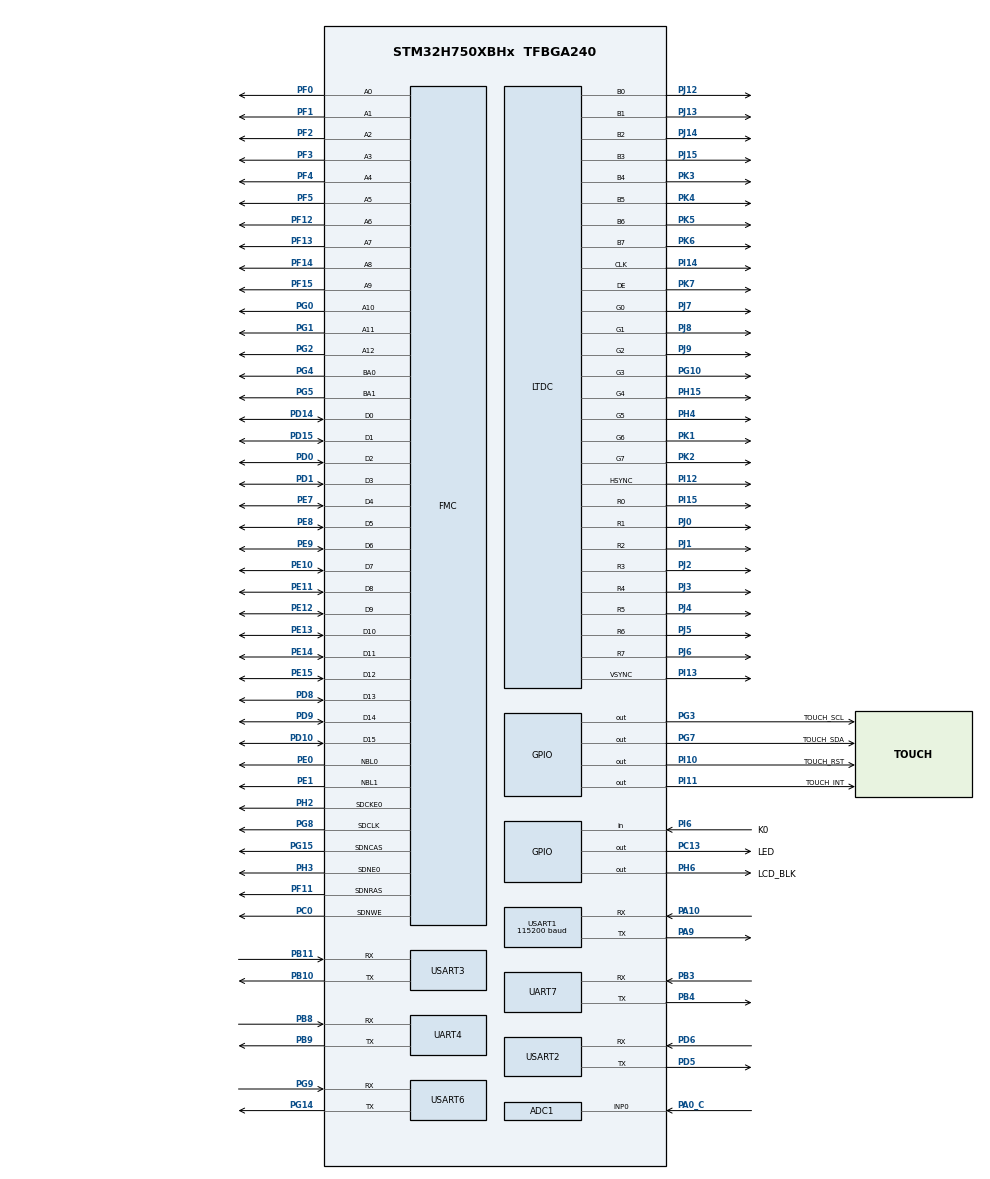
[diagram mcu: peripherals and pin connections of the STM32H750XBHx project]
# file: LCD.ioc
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ADC1.Channel-0\#ChannelRegularConversion=ADC_CHANNEL_0
ADC1.ClockPrescaler=ADC_CLOCK_ASYNC_DIV4
ADC1.ExternalTrigConv=ADC_EXTERNALTRIG_T8_TRGO
ADC1.NbrOfConversionFlag=1
ADC1.OffsetNumber-0\#ChannelRegularConversion=ADC_OFFSET_NONE
ADC1.OffsetSignedSaturation-0\#ChannelRegularConversion=DISABLE
ADC1.Rank-0\#ChannelRegularConversion=1
ADC1.Resolution=ADC_RESOLUTION_12B
ADC1.SamplingTime-0\#ChannelRegularConversion=ADC_SAMPLETIME_2CYCLES_5
ADC1.master=1
CORTEX_M7.AccessPermission-Cortex_Memory_Protection_Unit_Region0_Settings=MPU_REGION_FULL_ACCESS
CORTEX_M7.BaseAddress-Cortex_Memory_Protection_Unit_Region0_Settings=0xC0000000
CORTEX_M7.CPU_DCache=Enabled
CORTEX_M7.CPU_ICache=Enabled
CORTEX_M7.DisableExec-Cortex_Memory_Protection_Unit_Region0_Settings=MPU_INSTRUCTION_ACCESS_ENABLE
CORTEX_M7.Enable-Cortex_Memory_Protection_Unit_Region0_Settings=MPU_REGION_ENABLE
CORTEX_M7.Enable-Cortex_Memory_Protection_Unit_Region10_Settings=__NULL
CORTEX_M7.Enable-Cortex_Memory_Protection_Unit_Region11_Settings=__NULL
CORTEX_M7.Enable-Cortex_Memory_Protection_Unit_Region12_Settings=__NULL
CORTEX_M7.Enable-Cortex_Memory_Protection_Unit_Region13_Settings=__NULL
CORTEX_M7.Enable-Cortex_Memory_Protection_Unit_Region14_Settings=__NULL
CORTEX_M7.Enable-Cortex_Memory_Protection_Unit_Region15_Settings=__NULL
CORTEX_M7.Enable-Cortex_Memory_Protection_Unit_Region1_Settings=__NULL
CORTEX_M7.Enable-Cortex_Memory_Protection_Unit_Region2_Settings=__NULL
CORTEX_M7.Enable-Cortex_Memory_Protection_Unit_Region3_Settings=__NULL
CORTEX_M7.Enable-Cortex_Memory_Protection_Unit_Region4_Settings=__NULL
CORTEX_M7.Enable-Cortex_Memory_Protection_Unit_Region5_Settings=__NULL
CORTEX_M7.Enable-Cortex_Memory_Protection_Unit_Region6_Settings=__NULL
CORTEX_M7.Enable-Cortex_Memory_Protection_Unit_Region7_Settings=__NULL
CORTEX_M7.Enable-Cortex_Memory_Protection_Unit_Region8_Settings=__NULL
CORTEX_M7.Enable-Cortex_Memory_Protection_Unit_Region9_Settings=__NULL
CORTEX_M7.IsBufferable-Cortex_Memory_Protection_Unit_Region0_Settings=MPU_ACCESS_NOT_BUFFERABLE
CORTEX_M7.IsCacheable-Cortex_Memory_Protection_Unit_Region0_Settings=MPU_ACCESS_CACHEABLE
CORTEX_M7.IsShareable-Cortex_Memory_Protection_Unit_Region0_Settings=MPU_ACCESS_NOT_SHAREABLE
CORTEX_M7.MPU_Control=MPU_PRIVILEGED_DEFAULT
CORTEX_M7.Size-Cortex_Memory_Protection_Unit_Region0_Settings=MPU_REGION_SIZE_32MB
CORTEX_M7.TypeExtField-Cortex_Memory_Protection_Unit_Region0_Settings=MPU_TEX_LEVEL0
CORTEX_M7.default_mode_Activation=0
DMA2D.ColorMode=DMA2D_OUTPUT_RGB565
FMC.BankMapConfig=FMC_SWAPBMAP_DISABLE
FMC.CASLatency1=FMC_SDRAM_CAS_LATENCY_3
FMC.ColumnBitsNumber1=FMC_SDRAM_COLUMN_BITS_NUM_9
FMC.ExitSelfRefreshDelay1=7
FMC.LoadToActiveDelay1=2
FMC.RCDDelay1=2
FMC.RPDelay1=2
FMC.ReadBurst1=FMC_SDRAM_RBURST_ENABLE
FMC.ReadPipeDelay1=FMC_SDRAM_RPIPE_DELAY_1
FMC.RowBitsNumber1=FMC_SDRAM_ROW_BITS_NUM_13
FMC.RowCycleDelay1=7
FMC.SDBank1=FMC_SDRAM_BANK1
FMC.SDClockPeriod1=FMC_SDRAM_CLOCK_PERIOD_2
FMC.SelfRefreshTime1=4
FMC.WriteProtection1=FMC_SDRAM_WRITE_PROTECTION_DISABLE
FMC.WriteRecoveryTime1=3
FREERTOS.BinarySemaphores01=ADCValue,Dynamic,NULL,Available
FREERTOS.Tasks01=TouchgfxTask,24,4096,vTouchgfxTask,Default,NULL,Static,TouchgfxTaskBuffer,TouchgfxTaskControlBlock
FREERTOS.configTIMER_TASK_STACK_DEPTH=4096
LTDC.ActiveH=480
LTDC.ActiveW=800
LTDC.Alpha0_L0=0
LTDC.Alpha_L0=255
LTDC.BlendingFactor1_L0=LTDC_BLENDING_FACTOR1_CA
LTDC.BlendingFactor2_L0=LTDC_BLENDING_FACTOR2_CA
LTDC.Blue=0
LTDC.Blue_L0=0
LTDC.DEPolarity=LTDC_DEPOLARITY_AL
LTDC.FBStartAdress_L0=0xC0000000
LTDC.Green=0
LTDC.Green_L0=0
LTDC.HBP=80
LTDC.HFP=200
LTDC.HSPolarity=LTDC_HSPOLARITY_AL
LTDC.HSync=1
LTDC.ImageHeight_L0=480
LTDC.ImageWidth_L0=800
LTDC.Layers=0
LTDC.PCPolarity=LTDC_PCPOLARITY_IPC
LTDC.PixelFormat_L0=LTDC_PIXEL_FORMAT_RGB565
LTDC.Red=0
LTDC.Red_L0=0
LTDC.VBP=40
LTDC.VFP=22
LTDC.VSPolarity=LTDC_VSPOLARITY_AL
LTDC.VSync=1
LTDC.WindowX0_L0=0
LTDC.WindowX1_L0=800
LTDC.WindowY0_L0=0
LTDC.WindowY1_L0=480
Mcu.Family=STM32H7
Mcu.Name=STM32H750XBHx
Mcu.Package=TFBGA240
NVIC.ADC_IRQn=true\:7\:0\:true\:false\:true\:true\:true\:true\:true
NVIC.DMA2D_IRQn=true\:5\:0\:true\:false\:true\:true\:true\:true\:true
NVIC.LTDC_IRQn=true\:5\:0\:true\:false\:true\:true\:true\:true\:true
NVIC.PriorityGroup=NVIC_PRIORITYGROUP_4
NVIC.TIM17_IRQn=true\:5\:0\:false\:false\:true\:true\:true\:true\:true
NVIC.TIM6_DAC_IRQn=true\:15\:0\:false\:false\:true\:false\:false\:true\:true
NVIC.TIM8_UP_TIM13_IRQn=true\:5\:0\:false\:false\:true\:true\:true\:true\:true
NVIC.TimeBase=TIM6_DAC_IRQn
NVIC.TimeBaseIP=TIM6
NVIC.UART4_IRQn=true\:6\:0\:true\:false\:true\:true\:true\:true\:true
NVIC.UART7_IRQn=true\:6\:0\:true\:false\:true\:true\:true\:true\:true
NVIC.USART1_IRQn=true\:5\:0\:false\:false\:true\:true\:true\:true\:true
NVIC.USART2_IRQn=true\:5\:0\:false\:false\:true\:true\:true\:true\:true
NVIC.USART3_IRQn=true\:5\:0\:false\:false\:true\:true\:true\:true\:true
NVIC.USART6_IRQn=true\:5\:0\:false\:false\:true\:true\:true\:true\:true
PA0_C.Signal=ADCx_INP0
PA10.Mode=Asynchronous
PA10.Signal=USART1_RX
PA9.Mode=Asynchronous
PA9.Signal=USART1_TX
PB10.Mode=Asynchronous
PB10.Signal=USART3_TX
PB11.Mode=Asynchronous
PB11.Signal=USART3_RX
PB3\ (JTDO/TRACESWO).Mode=Asynchronous
PB3\ (JTDO/TRACESWO).Signal=UART7_RX
PB4\ (NJTRST).Mode=Asynchronous
PB4\ (NJTRST).Signal=UART7_TX
PB8.Mode=Asynchronous
PB8.Signal=UART4_RX
PB9.Mode=Asynchronous
PB9.Signal=UART4_TX
PC0.Signal=FMC_SDNWE
PC13.GPIO_Label=LED
PC13.PinState=GPIO_PIN_SET
PC13.Signal=GPIO_Output
PD0.Signal=FMC_D2_DA2
PD1.Signal=FMC_D3_DA3
PD10.Signal=FMC_D15_DA15
PD14.Signal=FMC_D0_DA0
PD15.Signal=FMC_D1_DA1
PD5.Mode=Asynchronous
PD5.Signal=USART2_TX
PD6.Mode=Asynchronous
PD6.Signal=USART2_RX
PD8.Signal=FMC_D13_DA13
PD9.Signal=FMC_D14_DA14
PE0.Signal=FMC_NBL0
PE1.Signal=FMC_NBL1
PE10.Signal=FMC_D7_DA7
PE11.Signal=FMC_D8_DA8
PE12.Signal=FMC_D9_DA9
PE13.Signal=FMC_D10_DA10
PE14.Signal=FMC_D11_DA11
PE15.Signal=FMC_D12_DA12
PE7.Signal=FMC_D4_DA4
PE8.Signal=FMC_D5_DA5
PE9.Signal=FMC_D6_DA6
PF0.Signal=FMC_A0
PF1.Signal=FMC_A1
PF11.Signal=FMC_SDNRAS
PF12.Signal=FMC_A6
PF13.Signal=FMC_A7
PF14.Signal=FMC_A8
PF15.Signal=FMC_A9
PF2.Signal=FMC_A2
PF3.Signal=FMC_A3
PF4.Signal=FMC_A4
PF5.Signal=FMC_A5
PF7.GPIO_Speed=GPIO_SPEED_FREQ_VERY_HIGH
PF7.Signal=QUADSPI_BK1_IO2
PF8.GPIO_Speed=GPIO_SPEED_FREQ_VERY_HIGH
PF8.Signal=QUADSPI_BK1_IO0
PF9.GPIO_Speed=GPIO_SPEED_FREQ_VERY_HIGH
PF9.Signal=QUADSPI_BK1_IO1
PG0.Signal=FMC_A10
PG1.Signal=FMC_A11
PG10.GPIO_Speed=GPIO_SPEED_FREQ_VERY_HIGH
PG10.Mode=RGB888
PG10.Signal=LTDC_G3
PG14.Mode=Asynchronous
PG14.Signal=USART6_TX
PG15.Signal=FMC_SDNCAS
PG2.Signal=FMC_A12
PG3.GPIO_Label=TOUCH_SCL
PG3.GPIO_ModeDefaultOutputPP=GPIO_MODE_OUTPUT_OD
PG3.GPIO_PuPd=GPIO_NOPULL
PG3.PinState=GPIO_PIN_SET
PG3.Signal=GPIO_Output
PG4.Signal=FMC_A14_BA0
PG5.Signal=FMC_A15_BA1
PG6.GPIO_Speed=GPIO_SPEED_FREQ_VERY_HIGH
PG6.Signal=QUADSPI_BK1_NCS
PG7.GPIO_Label=TOUCH_SDA
PG7.GPIO_ModeDefaultOutputPP=GPIO_MODE_OUTPUT_OD
PG7.GPIO_PuPd=GPIO_NOPULL
PG7.PinState=GPIO_PIN_SET
PG7.Signal=GPIO_Output
PG8.Signal=FMC_SDCLK
PG9.Mode=Asynchronous
PG9.Signal=USART6_RX
PH0-OSC_IN\ (PH0).Mode=HSE-External-Oscillator
PH0-OSC_IN\ (PH0).Signal=RCC_OSC_IN
PH1-OSC_OUT\ (PH1).Mode=HSE-External-Oscillator
PH1-OSC_OUT\ (PH1).Signal=RCC_OSC_OUT
PH10.GPIO_Speed=GPIO_SPEED_FREQ_VERY_HIGH
PH10.Signal=DCMI_D1
PH12.GPIO_Speed=GPIO_SPEED_FREQ_VERY_HIGH
PH12.Signal=DCMI_D3
PH15.GPIO_Speed=GPIO_SPEED_FREQ_VERY_HIGH
PH15.Mode=RGB888
PH15.Signal=LTDC_G4
PH2.Mode=SdramChipSelect1_1
PH2.Signal=FMC_SDCKE0
PH3.Mode=SdramChipSelect1_1
PH3.Signal=FMC_SDNE0
PH4.GPIO_Speed=GPIO_SPEED_FREQ_VERY_HIGH
PH4.Mode=RGB888
PH4.Signal=LTDC_G5
PH6.GPIO_Label=LCD_BLK
PH6.PinState=GPIO_PIN_SET
PH6.Signal=GPIO_Output
PH9.GPIO_Speed=GPIO_SPEED_FREQ_VERY_HIGH
PH9.Signal=DCMI_D0
PI10.GPIO_Label=TOUCH_RST
PI10.GPIO_PuPd=GPIO_PULLUP
PI10.PinState=GPIO_PIN_SET
PI10.Signal=GPIO_Output
PI11.GPIO_Label=TOUCH_INT
PI11.GPIO_PuPd=GPIO_PULLUP
PI11.Signal=GPIO_Output
PI12.GPIO_Speed=GPIO_SPEED_FREQ_VERY_HIGH
PI12.Mode=RGB888
PI12.Signal=LTDC_HSYNC
PI13.GPIO_Speed=GPIO_SPEED_FREQ_VERY_HIGH
PI13.Mode=RGB888
PI13.Signal=LTDC_VSYNC
PI14.GPIO_Speed=GPIO_SPEED_FREQ_VERY_HIGH
PI14.Mode=RGB888
PI14.Signal=LTDC_CLK
PI15.GPIO_Speed=GPIO_SPEED_FREQ_VERY_HIGH
PI15.Mode=RGB888
PI15.Signal=LTDC_R0
PI6.GPIO_Label=K0
PI6.GPIO_PuPd=GPIO_PULLUP
PI6.Signal=GPIO_Input
PJ0.GPIO_Speed=GPIO_SPEED_FREQ_VERY_HIGH
PJ0.Mode=RGB888
PJ0.Signal=LTDC_R1
PJ1.GPIO_Speed=GPIO_SPEED_FREQ_VERY_HIGH
PJ1.Mode=RGB888
PJ1.Signal=LTDC_R2
PJ12.GPIO_Speed=GPIO_SPEED_FREQ_VERY_HIGH
PJ12.Mode=RGB888
PJ12.Signal=LTDC_B0
PJ13.GPIO_Speed=GPIO_SPEED_FREQ_VERY_HIGH
PJ13.Mode=RGB888
PJ13.Signal=LTDC_B1
PJ14.GPIO_Speed=GPIO_SPEED_FREQ_VERY_HIGH
PJ14.Mode=RGB888
PJ14.Signal=LTDC_B2
PJ15.GPIO_Speed=GPIO_SPEED_FREQ_VERY_HIGH
PJ15.Mode=RGB888
PJ15.Signal=LTDC_B3
PJ2.GPIO_Speed=GPIO_SPEED_FREQ_VERY_HIGH
PJ2.Mode=RGB888
PJ2.Signal=LTDC_R3
PJ3.GPIO_Speed=GPIO_SPEED_FREQ_VERY_HIGH
PJ3.Mode=RGB888
PJ3.Signal=LTDC_R4
PJ4.GPIO_Speed=GPIO_SPEED_FREQ_VERY_HIGH
PJ4.Mode=RGB888
PJ4.Signal=LTDC_R5
PJ5.GPIO_Speed=GPIO_SPEED_FREQ_VERY_HIGH
PJ5.Mode=RGB888
PJ5.Signal=LTDC_R6
PJ6.GPIO_Speed=GPIO_SPEED_FREQ_VERY_HIGH
PJ6.Mode=RGB888
PJ6.Signal=LTDC_R7
PJ7.GPIO_Speed=GPIO_SPEED_FREQ_VERY_HIGH
PJ7.Mode=RGB888
PJ7.Signal=LTDC_G0
PJ8.GPIO_Speed=GPIO_SPEED_FREQ_VERY_HIGH
PJ8.Mode=RGB888
PJ8.Signal=LTDC_G1
PJ9.GPIO_Speed=GPIO_SPEED_FREQ_VERY_HIGH
PJ9.Mode=RGB888
PJ9.Signal=LTDC_G2
PK1.GPIO_Speed=GPIO_SPEED_FREQ_VERY_HIGH
PK1.Mode=RGB888
PK1.Signal=LTDC_G6
PK2.GPIO_Speed=GPIO_SPEED_FREQ_VERY_HIGH
PK2.Mode=RGB888
PK2.Signal=LTDC_G7
PK3.GPIO_Speed=GPIO_SPEED_FREQ_VERY_HIGH
PK3.Mode=RGB888
PK3.Signal=LTDC_B4
PK4.GPIO_Speed=GPIO_SPEED_FREQ_VERY_HIGH
PK4.Mode=RGB888
PK4.Signal=LTDC_B5
PK5.GPIO_Speed=GPIO_SPEED_FREQ_VERY_HIGH
PK5.Mode=RGB888
PK5.Signal=LTDC_B6
PK6.GPIO_Speed=GPIO_SPEED_FREQ_VERY_HIGH
PK6.Mode=RGB888
PK6.Signal=LTDC_B7
PK7.GPIO_Speed=GPIO_SPEED_FREQ_VERY_HIGH
PK7.Mode=RGB888
PK7.Signal=LTDC_DE
ProjectManager.HeapSize=0x2000
ProjectManager.StackSize=0x2000
ProjectManager.TargetToolchain=MDK-ARM V5.32
RCC.ADCFreq_Value=1171875
RCC.APB1Freq_Value=120000000
RCC.APB2Freq_Value=120000000
RCC.APB3Freq_Value=120000000
RCC.APB4Freq_Value=120000000
RCC.CortexFreq_Value=480000000
RCC.D1PPRE=RCC_APB3_DIV2
RCC.D2PPRE1=RCC_APB1_DIV2
RCC.D2PPRE2=RCC_APB2_DIV2
RCC.D3PPRE=RCC_APB4_DIV2
RCC.DIVM1=5
RCC.DIVM2=2
RCC.DIVM3=25
RCC.DIVN1=192
RCC.DIVN2=12
RCC.DIVN3=330
RCC.DIVP2=128
RCC.DIVQ1=4
RCC.DIVR3=10
RCC.FLatency=FLASH_LATENCY_4
RCC.HCLKFreq_Value=240000000
RCC.HPRE=RCC_HCLK_DIV2
RCC.PLL1_VCI_Range=RCC_PLL1VCIRANGE_2
RCC.PLL1_VCI_Range-AdvancedSettings=RCC_PLL1VCIRANGE_0
RCC.PLL3FRACN=0
RCC.PLL3_VCI_Range=RCC_PLL3VCIRANGE_0
RCC.PLLFRACN=0
RCC.PLLSourceVirtual=RCC_PLLSOURCE_HSE
RCC.PWR_Regulator_Voltage_Scale=PWR_REGULATOR_VOLTAGE_SCALE0
RCC.SYSCLKFreq_VALUE=480000000
RCC.SYSCLKSource=RCC_SYSCLKSOURCE_PLLCLK
RCC.USBFreq_Value=240000000
SH.ADCx_INP0.0=ADC1_INP0,IN0-Single-Ended
SH.FMC_A0.0=FMC_A0,13b-sda1
SH.FMC_A1.0=FMC_A1,13b-sda1
SH.FMC_A10.0=FMC_A10,13b-sda1
SH.FMC_A11.0=FMC_A11,13b-sda1
SH.FMC_A12.0=FMC_A12,13b-sda1
SH.FMC_A14_BA0.0=FMC_BA0,FourSdramBanks1
SH.FMC_A15_BA1.0=FMC_BA1,FourSdramBanks1
SH.FMC_A2.0=FMC_A2,13b-sda1
SH.FMC_A3.0=FMC_A3,13b-sda1
SH.FMC_A4.0=FMC_A4,13b-sda1
SH.FMC_A5.0=FMC_A5,13b-sda1
SH.FMC_A6.0=FMC_A6,13b-sda1
SH.FMC_A7.0=FMC_A7,13b-sda1
SH.FMC_A8.0=FMC_A8,13b-sda1
SH.FMC_A9.0=FMC_A9,13b-sda1
SH.FMC_D0_DA0.0=FMC_D0,sd-16b-d1
SH.FMC_D10_DA10.0=FMC_D10,sd-16b-d1
SH.FMC_D11_DA11.0=FMC_D11,sd-16b-d1
SH.FMC_D12_DA12.0=FMC_D12,sd-16b-d1
SH.FMC_D13_DA13.0=FMC_D13,sd-16b-d1
SH.FMC_D14_DA14.0=FMC_D14,sd-16b-d1
SH.FMC_D15_DA15.0=FMC_D15,sd-16b-d1
SH.FMC_D1_DA1.0=FMC_D1,sd-16b-d1
SH.FMC_D2_DA2.0=FMC_D2,sd-16b-d1
SH.FMC_D3_DA3.0=FMC_D3,sd-16b-d1
SH.FMC_D4_DA4.0=FMC_D4,sd-16b-d1
SH.FMC_D5_DA5.0=FMC_D5,sd-16b-d1
SH.FMC_D6_DA6.0=FMC_D6,sd-16b-d1
SH.FMC_D7_DA7.0=FMC_D7,sd-16b-d1
SH.FMC_D8_DA8.0=FMC_D8,sd-16b-d1
SH.FMC_D9_DA9.0=FMC_D9,sd-16b-d1
SH.FMC_NBL0.0=FMC_NBL0,Sd2ByteEnable1
SH.FMC_NBL1.0=FMC_NBL1,Sd2ByteEnable1
SH.FMC_SDCLK.0=FMC_SDCLK,13b-sda1
SH.FMC_SDNCAS.0=FMC_SDNCAS,13b-sda1
SH.FMC_SDNRAS.0=FMC_SDNRAS,13b-sda1
SH.FMC_SDNWE.0=FMC_SDNWE,13b-sda1
STMicroelectronics.X-CUBE-TOUCHGFX.4.25.0.ApplicationCcGraphicsJjApplication=TouchGFXOoGenerator
STMicroelectronics.X-CUBE-TOUCHGFX.4.25.0.tgfx_address1=0xC0000000
STMicroelectronics.X-CUBE-TOUCHGFX.4.25.0.tgfx_address2=0xC00BB800
STMicroelectronics.X-CUBE-TOUCHGFX.4.25.0.tgfx_buffering_strategy=Double
STMicroelectronics.X-CUBE-TOUCHGFX.4.25.0.tgfx_custom_height=480
STMicroelectronics.X-CUBE-TOUCHGFX.4.25.0.tgfx_display_interface=disp_ltdc
STMicroelectronics.X-CUBE-TOUCHGFX.4.25.0.tgfx_hardware_accelerator=dma_2d
STMicroelectronics.X-CUBE-TOUCHGFX.4.25.0.tgfx_location=By Address
STMicroelectronics.X-CUBE-TOUCHGFX.4.25.0.tgfx_video=Disabled
STMicroelectronics.X-CUBE-TOUCHGFX.4.25.0.tgfx_video_height=480
STMicroelectronics.X-CUBE-TOUCHGFX.4.25.0.tgfx_video_strategy=1
STMicroelectronics.X-CUBE-TOUCHGFX.4.25.0.tgfx_video_width=800
STMicroelectronics.X-CUBE-TOUCHGFX.4.25.0.tgfx_vsync=vsync_ltdc
STMicroelectronics.X-CUBE-TOUCHGFX.4.25.0_IsPackSelfContextualization=true
TIM17.Channel=TIM_CHANNEL_1
TIM17.Period=10000-1
TIM17.Prescaler=480-1
TIM8.Channel-Output\ Compare1\ No\ Output=TIM_CHANNEL_1
TIM8.Period=10000-1
TIM8.Prescaler=480-1
TIM8.TIM_MasterOutputTrigger=TIM_TRGO_UPDATE
USART1.AutoBaudRateEnableParam=UART_ADVFEATURE_AUTOBAUDRATE_DISABLE
USART1.BaudRate=115200
USART1.ClockPrescaler=PRESCALER_DIV1
USART1.DMADisableonRxErrorParam=ADVFEATURE_DMA_ENABLEONRXERROR
USART1.DataInvertParam=ADVFEATURE_DATAINV_DISABLE
USART1.FIFOMode=FIFOMODE_DISABLE
USART1.MSBFirstParam=ADVFEATURE_MSBFIRST_DISABLE
USART1.Mode=MODE_TX_RX
USART1.OneBitSampling=UART_ONE_BIT_SAMPLE_DISABLE
USART1.OverSampling=UART_OVERSAMPLING_16
USART1.OverrunDisableParam=ADVFEATURE_OVERRUN_ENABLE
USART1.Parity=PARITY_NONE
USART1.RXFIFOThreshold=RXFIFO_THRESHOLD_1EIGHTHFULL
USART1.RxPinLevelInvertParam=ADVFEATURE_RXINV_DISABLE
USART1.StopBits=STOPBITS_1
USART1.SwapParam=ADVFEATURE_SWAP_DISABLE
USART1.TXFIFOThreshold=TXFIFO_THRESHOLD_1EIGHTHFULL
USART1.TxPinLevelInvertParam=ADVFEATURE_TXINV_DISABLE
USART1.VirtualMode-Asynchronous=VM_ASYNC
USART1.WordLength=WORDLENGTH_8B
USART2.VirtualMode-Asynchronous=VM_ASYNC
USART3.VirtualMode-Asynchronous=VM_ASYNC
USART6.VirtualMode-Asynchronous=VM_ASYNC
VP_CRC_VS_CRC.Mode=CRC_Activate
VP_DMA2D_VS_DMA2D.Mode=DMA2D_Activate
VP_FREERTOS_VS_CMSIS_V2.Mode=CMSIS_V2
VP_MEMORYMAP_VS_MEMORYMAP.Mode=CurAppReg
VP_STMicroelectronics.X-CUBE-TOUCHGFX_VS_GraphicsJjApplication_4.25.0.Mode=GraphicsJjApplication
VP_SYS_VS_tim6.Mode=TIM6
VP_TIM17_VS_ClockSourceINT.Mode=Enable_Timer
VP_TIM17_VS_no_output1.Mode=Output Compare1 No Output
VP_TIM8_VS_ClockSourceINT.Mode=Internal
VP_TIM8_VS_no_output1.Mode=Output Compare1 No Output
board=custom

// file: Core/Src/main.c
/* USER CODE BEGIN Header */
/**
  ******************************************************************************
  * @file           : main.c
  * @brief          : Main program body
  ******************************************************************************
  * @attention
  *
  * Copyright (c) 2025 STMicroelectronics.
  * All rights reserved.
  *
  * This software is licensed under terms that can be found in the LICENSE file
  * in the root directory of this software component.
  * If no LICENSE file comes with this software, it is provided AS-IS.
  *
  ******************************************************************************
  */
/* USER CODE END Header */
#include "main.h"
#include "cmsis_os.h"
#include "app_touchgfx.h"

/* USER CODE BEGIN Includes */
#include "MyHFile.h"
/* USER CODE END Includes */

typedef StaticTask_t osStaticThreadDef_t;

ADC_HandleTypeDef hadc1;

CRC_HandleTypeDef hcrc;

DMA2D_HandleTypeDef hdma2d;

LTDC_HandleTypeDef hltdc;

TIM_HandleTypeDef htim8;
TIM_HandleTypeDef htim17;

UART_HandleTypeDef huart4;
UART_HandleTypeDef huart7;
UART_HandleTypeDef huart1;
UART_HandleTypeDef huart2;
UART_HandleTypeDef huart3;
UART_HandleTypeDef huart6;

SDRAM_HandleTypeDef hsdram1;

/* Definitions for TouchgfxTask */
osThreadId_t TouchgfxTaskHandle;
uint32_t TouchgfxTaskBuffer[ 4096 ];
osStaticThreadDef_t TouchgfxTaskControlBlock;
const osThreadAttr_t TouchgfxTask_attributes = {
  .name = "TouchgfxTask",
  .cb_mem = &TouchgfxTaskControlBlock,
  .cb_size = sizeof(TouchgfxTaskControlBlock),
  .stack_mem = &TouchgfxTaskBuffer[0],
  .stack_size = sizeof(TouchgfxTaskBuffer),
  .priority = (osPriority_t) osPriorityNormal,
};
/* Definitions for ADCValue */
osSemaphoreId_t ADCValueHandle;
const osSemaphoreAttr_t ADCValue_attributes = {
  .name = "ADCValue"
};

void SystemClock_Config(void);
static void MPU_Config(void);
static void MX_GPIO_Init(void);
static void MX_USART1_UART_Init(void);
static void MX_FMC_Init(void);
static void MX_LTDC_Init(void);
static void MX_DMA2D_Init(void);
static void MX_CRC_Init(void);
static void MX_TIM17_Init(void);
static void MX_ADC1_Init(void);
static void MX_TIM8_Init(void);
static void MX_USART2_UART_Init(void);
static void MX_UART7_Init(void);
static void MX_UART4_Init(void);
static void MX_USART6_UART_Init(void);
static void MX_USART3_UART_Init(void);
void vTouchgfxTask(void *argument);

int main(void)
{

  /* MPU Configuration--------------------------------------------------------*/
  MPU_Config();

  /* Enable the CPU Cache */

  /* Enable I-Cache---------------------------------------------------------*/
  SCB_EnableICache();

  /* Enable D-Cache---------------------------------------------------------*/
  SCB_EnableDCache();

  /* MCU Configuration--------------------------------------------------------*/

  /* Reset of all peripherals, Initializes the Flash interface and the Systick. */
  HAL_Init();

  /* Configure the system clock */
  SystemClock_Config();

  /* Initialize all configured peripherals */
  MX_GPIO_Init();
  MX_USART1_UART_Init();
  MX_FMC_Init();
  MX_LTDC_Init();
  MX_DMA2D_Init();
  MX_CRC_Init();
  MX_TIM17_Init();
  MX_ADC1_Init();
  MX_TIM8_Init();
  MX_USART2_UART_Init();
  MX_UART7_Init();
  MX_UART4_Init();
  MX_USART6_UART_Init();
  MX_USART3_UART_Init();
  MX_TouchGFX_Init();
  /* Call PreOsInit function */
  MX_TouchGFX_PreOSInit();
  /* USER CODE BEGIN 2 */

  Time_Init();

  HAL_ADC_Start_IT(&hadc1);

  HAL_TIM_Base_Start(&htim8);
  UART_Init();

  //AIR780EX_Init();
//  AIR780EX_Transmit("njibhu");

  printf("OK\r\n");
  /* USER CODE END 2 */

  /* Init scheduler */
  osKernelInitialize();

  /* Create the semaphores(s) */
  /* creation of ADCValue */
  ADCValueHandle = osSemaphoreNew(1, 1, &ADCValue_attributes);

  /* Create the thread(s) */
  /* creation of TouchgfxTask */
  TouchgfxTaskHandle = osThreadNew(vTouchgfxTask, NULL, &TouchgfxTask_attributes);

  /* USER CODE BEGIN RTOS_THREADS */
  /* add threads, ... */
  InitTaskHandle = osThreadNew(vInitTask, NULL, &InitTask_attributes);
  /* USER CODE END RTOS_THREADS */

  /* Start scheduler */
  osKernelStart();

  /* We should never get here as control is now taken by the scheduler */

  /* Infinite loop */
  while (1)
  {

  }
}

void SystemClock_Config(void)
{
  RCC_OscInitTypeDef RCC_OscInitStruct = {0};
  RCC_ClkInitTypeDef RCC_ClkInitStruct = {0};

  /** Supply configuration update enable
  */
  HAL_PWREx_ConfigSupply(PWR_LDO_SUPPLY);

  /** Configure the main internal regulator output voltage
  */
  __HAL_PWR_VOLTAGESCALING_CONFIG(PWR_REGULATOR_VOLTAGE_SCALE0);

  while(!__HAL_PWR_GET_FLAG(PWR_FLAG_VOSRDY)) {}

  /** Initializes the RCC Oscillators according to the specified parameters
  * in the RCC_OscInitTypeDef structure.
  */
  RCC_OscInitStruct.OscillatorType = RCC_OSCILLATORTYPE_HSE;
  RCC_OscInitStruct.HSEState = RCC_HSE_ON;
  RCC_OscInitStruct.PLL.PLLState = RCC_PLL_ON;
  RCC_OscInitStruct.PLL.PLLSource = RCC_PLLSOURCE_HSE;
  RCC_OscInitStruct.PLL.PLLM = 5;
  RCC_OscInitStruct.PLL.PLLN = 192;
  RCC_OscInitStruct.PLL.PLLP = 2;
  RCC_OscInitStruct.PLL.PLLQ = 4;
  RCC_OscInitStruct.PLL.PLLR = 2;
  RCC_OscInitStruct.PLL.PLLRGE = RCC_PLL1VCIRANGE_2;
  RCC_OscInitStruct.PLL.PLLVCOSEL = RCC_PLL1VCOWIDE;
  RCC_OscInitStruct.PLL.PLLFRACN = 0;
  if (HAL_RCC_OscConfig(&RCC_OscInitStruct) != HAL_OK)
  {
    Error_Handler();
  }

  /** Initializes the CPU, AHB and APB buses clocks
  */
  RCC_ClkInitStruct.ClockType = RCC_CLOCKTYPE_HCLK|RCC_CLOCKTYPE_SYSCLK
                              |RCC_CLOCKTYPE_PCLK1|RCC_CLOCKTYPE_PCLK2
                              |RCC_CLOCKTYPE_D3PCLK1|RCC_CLOCKTYPE_D1PCLK1;
  RCC_ClkInitStruct.SYSCLKSource = RCC_SYSCLKSOURCE_PLLCLK;
  RCC_ClkInitStruct.SYSCLKDivider = RCC_SYSCLK_DIV1;
  RCC_ClkInitStruct.AHBCLKDivider = RCC_HCLK_DIV2;
  RCC_ClkInitStruct.APB3CLKDivider = RCC_APB3_DIV2;
  RCC_ClkInitStruct.APB1CLKDivider = RCC_APB1_DIV2;
  RCC_ClkInitStruct.APB2CLKDivider = RCC_APB2_DIV2;
  RCC_ClkInitStruct.APB4CLKDivider = RCC_APB4_DIV2;

  if (HAL_RCC_ClockConfig(&RCC_ClkInitStruct, FLASH_LATENCY_4) != HAL_OK)
  {
    Error_Handler();
  }
}

static void MX_ADC1_Init(void)
{

  ADC_MultiModeTypeDef multimode = {0};
  ADC_ChannelConfTypeDef sConfig = {0};

  /** Common config
  */
  hadc1.Instance = ADC1;
  hadc1.Init.ClockPrescaler = ADC_CLOCK_ASYNC_DIV4;
  hadc1.Init.Resolution = ADC_RESOLUTION_12B;
  hadc1.Init.ScanConvMode = ADC_SCAN_DISABLE;
  hadc1.Init.EOCSelection = ADC_EOC_SINGLE_CONV;
  hadc1.Init.LowPowerAutoWait = DISABLE;
  hadc1.Init.ContinuousConvMode = DISABLE;
  hadc1.Init.NbrOfConversion = 1;
  hadc1.Init.DiscontinuousConvMode = DISABLE;
  hadc1.Init.ExternalTrigConv = ADC_EXTERNALTRIG_T8_TRGO;
  hadc1.Init.ExternalTrigConvEdge = ADC_EXTERNALTRIGCONVEDGE_RISING;
  hadc1.Init.ConversionDataManagement = ADC_CONVERSIONDATA_DR;
  hadc1.Init.Overrun = ADC_OVR_DATA_PRESERVED;
  hadc1.Init.LeftBitShift = ADC_LEFTBITSHIFT_NONE;
  hadc1.Init.OversamplingMode = DISABLE;
  hadc1.Init.Oversampling.Ratio = 1;
  if (HAL_ADC_Init(&hadc1) != HAL_OK)
  {
    Error_Handler();
  }

  /** Configure the ADC multi-mode
  */
  multimode.Mode = ADC_MODE_INDEPENDENT;
  if (HAL_ADCEx_MultiModeConfigChannel(&hadc1, &multimode) != HAL_OK)
  {
    Error_Handler();
  }

  /** Configure Regular Channel
  */
  sConfig.Channel = ADC_CHANNEL_0;
  sConfig.Rank = ADC_REGULAR_RANK_1;
  sConfig.SamplingTime = ADC_SAMPLETIME_2CYCLES_5;
  sConfig.SingleDiff = ADC_SINGLE_ENDED;
  sConfig.OffsetNumber = ADC_OFFSET_NONE;
  sConfig.Offset = 0;
  sConfig.OffsetSignedSaturation = DISABLE;
  if (HAL_ADC_ConfigChannel(&hadc1, &sConfig) != HAL_OK)
  {
    Error_Handler();
  }

}

static void MX_CRC_Init(void)
{

  hcrc.Instance = CRC;
  hcrc.Init.DefaultPolynomialUse = DEFAULT_POLYNOMIAL_ENABLE;
  hcrc.Init.DefaultInitValueUse = DEFAULT_INIT_VALUE_ENABLE;
  hcrc.Init.InputDataInversionMode = CRC_INPUTDATA_INVERSION_NONE;
  hcrc.Init.OutputDataInversionMode = CRC_OUTPUTDATA_INVERSION_DISABLE;
  hcrc.InputDataFormat = CRC_INPUTDATA_FORMAT_BYTES;
  if (HAL_CRC_Init(&hcrc) != HAL_OK)
  {
    Error_Handler();
  }

}

static void MX_DMA2D_Init(void)
{

  hdma2d.Instance = DMA2D;
  hdma2d.Init.Mode = DMA2D_M2M;
  hdma2d.Init.ColorMode = DMA2D_OUTPUT_RGB565;
  hdma2d.Init.OutputOffset = 0;
  hdma2d.LayerCfg[1].InputOffset = 0;
  hdma2d.LayerCfg[1].InputColorMode = DMA2D_INPUT_RGB565;
  hdma2d.LayerCfg[1].AlphaMode = DMA2D_NO_MODIF_ALPHA;
  hdma2d.LayerCfg[1].InputAlpha = 0;
  hdma2d.LayerCfg[1].AlphaInverted = DMA2D_REGULAR_ALPHA;
  hdma2d.LayerCfg[1].RedBlueSwap = DMA2D_RB_REGULAR;
  hdma2d.LayerCfg[1].ChromaSubSampling = DMA2D_NO_CSS;
  if (HAL_DMA2D_Init(&hdma2d) != HAL_OK)
  {
    Error_Handler();
  }
  if (HAL_DMA2D_ConfigLayer(&hdma2d, 1) != HAL_OK)
  {
    Error_Handler();
  }

}

static void MX_LTDC_Init(void)
{

  LTDC_LayerCfgTypeDef pLayerCfg = {0};

  hltdc.Instance = LTDC;
  hltdc.Init.HSPolarity = LTDC_HSPOLARITY_AL;
  hltdc.Init.VSPolarity = LTDC_VSPOLARITY_AL;
  hltdc.Init.DEPolarity = LTDC_DEPOLARITY_AL;
  hltdc.Init.PCPolarity = LTDC_PCPOLARITY_IPC;
  hltdc.Init.HorizontalSync = 0;
  hltdc.Init.VerticalSync = 0;
  hltdc.Init.AccumulatedHBP = 80;
  hltdc.Init.AccumulatedVBP = 40;
  hltdc.Init.AccumulatedActiveW = 880;
  hltdc.Init.AccumulatedActiveH = 520;
  hltdc.Init.TotalWidth = 1080;
  hltdc.Init.TotalHeigh = 542;
  hltdc.Init.Backcolor.Blue = 0;
  hltdc.Init.Backcolor.Green = 0;
  hltdc.Init.Backcolor.Red = 0;
  if (HAL_LTDC_Init(&hltdc) != HAL_OK)
  {
    Error_Handler();
  }
  pLayerCfg.WindowX0 = 0;
  pLayerCfg.WindowX1 = 800;
  pLayerCfg.WindowY0 = 0;
  pLayerCfg.WindowY1 = 480;
  pLayerCfg.PixelFormat = LTDC_PIXEL_FORMAT_RGB565;
  pLayerCfg.Alpha = 255;
  pLayerCfg.Alpha0 = 0;
  pLayerCfg.BlendingFactor1 = LTDC_BLENDING_FACTOR1_CA;
  pLayerCfg.BlendingFactor2 = LTDC_BLENDING_FACTOR2_CA;
  pLayerCfg.FBStartAdress = 0xC0000000;
  pLayerCfg.ImageWidth = 800;
  pLayerCfg.ImageHeight = 480;
  pLayerCfg.Backcolor.Blue = 0;
  pLayerCfg.Backcolor.Green = 0;
  pLayerCfg.Backcolor.Red = 0;
  if (HAL_LTDC_ConfigLayer(&hltdc, &pLayerCfg, 0) != HAL_OK)
  {
    Error_Handler();
  }
  /* USER CODE BEGIN LTDC_Init 2 */
  	HAL_LTDC_ProgramLineEvent(&hltdc,0);			// �������жϣ���0��
	HAL_NVIC_SetPriority(LTDC_IRQn, 0xE, 0);		// �������ȼ�
	HAL_NVIC_EnableIRQ(LTDC_IRQn);					// ʹ���ж�
  /* USER CODE END LTDC_Init 2 */

}

static void MX_TIM8_Init(void)
{

  TIM_ClockConfigTypeDef sClockSourceConfig = {0};
  TIM_MasterConfigTypeDef sMasterConfig = {0};
  TIM_OC_InitTypeDef sConfigOC = {0};
  TIM_BreakDeadTimeConfigTypeDef sBreakDeadTimeConfig = {0};

  htim8.Instance = TIM8;
  htim8.Init.Prescaler = 480-1;
  htim8.Init.CounterMode = TIM_COUNTERMODE_UP;
  htim8.Init.Period = 10000-1;
  htim8.Init.ClockDivision = TIM_CLOCKDIVISION_DIV1;
  htim8.Init.RepetitionCounter = 0;
  htim8.Init.AutoReloadPreload = TIM_AUTORELOAD_PRELOAD_DISABLE;
  if (HAL_TIM_Base_Init(&htim8) != HAL_OK)
  {
    Error_Handler();
  }
  sClockSourceConfig.ClockSource = TIM_CLOCKSOURCE_INTERNAL;
  if (HAL_TIM_ConfigClockSource(&htim8, &sClockSourceConfig) != HAL_OK)
  {
    Error_Handler();
  }
  if (HAL_TIM_OC_Init(&htim8) != HAL_OK)
  {
    Error_Handler();
  }
  sMasterConfig.MasterOutputTrigger = TIM_TRGO_UPDATE;
  sMasterConfig.MasterOutputTrigger2 = TIM_TRGO2_RESET;
  sMasterConfig.MasterSlaveMode = TIM_MASTERSLAVEMODE_DISABLE;
  if (HAL_TIMEx_MasterConfigSynchronization(&htim8, &sMasterConfig) != HAL_OK)
  {
    Error_Handler();
  }
  sConfigOC.OCMode = TIM_OCMODE_TIMING;
  sConfigOC.Pulse = 0;
  sConfigOC.OCPolarity = TIM_OCPOLARITY_HIGH;
  sConfigOC.OCNPolarity = TIM_OCNPOLARITY_HIGH;
  sConfigOC.OCFastMode = TIM_OCFAST_DISABLE;
  sConfigOC.OCIdleState = TIM_OCIDLESTATE_RESET;
  sConfigOC.OCNIdleState = TIM_OCNIDLESTATE_RESET;
  if (HAL_TIM_OC_ConfigChannel(&htim8, &sConfigOC, TIM_CHANNEL_1) != HAL_OK)
  {
    Error_Handler();
  }
  sBreakDeadTimeConfig.OffStateRunMode = TIM_OSSR_DISABLE;
  sBreakDeadTimeConfig.OffStateIDLEMode = TIM_OSSI_DISABLE;
  sBreakDeadTimeConfig.LockLevel = TIM_LOCKLEVEL_OFF;
  sBreakDeadTimeConfig.DeadTime = 0;
  sBreakDeadTimeConfig.BreakState = TIM_BREAK_DISABLE;
  sBreakDeadTimeConfig.BreakPolarity = TIM_BREAKPOLARITY_HIGH;
  sBreakDeadTimeConfig.BreakFilter = 0;
  sBreakDeadTimeConfig.Break2State = TIM_BREAK2_DISABLE;
  sBreakDeadTimeConfig.Break2Polarity = TIM_BREAK2POLARITY_HIGH;
  sBreakDeadTimeConfig.Break2Filter = 0;
  sBreakDeadTimeConfig.AutomaticOutput = TIM_AUTOMATICOUTPUT_DISABLE;
  if (HAL_TIMEx_ConfigBreakDeadTime(&htim8, &sBreakDeadTimeConfig) != HAL_OK)
  {
    Error_Handler();
  }

}

static void MX_TIM17_Init(void)
{

  TIM_OC_InitTypeDef sConfigOC = {0};
  TIM_BreakDeadTimeConfigTypeDef sBreakDeadTimeConfig = {0};

  htim17.Instance = TIM17;
  htim17.Init.Prescaler = 480-1;
  htim17.Init.CounterMode = TIM_COUNTERMODE_UP;
  htim17.Init.Period = 10000-1;
  htim17.Init.ClockDivision = TIM_CLOCKDIVISION_DIV1;
  htim17.Init.RepetitionCounter = 0;
  htim17.Init.AutoReloadPreload = TIM_AUTORELOAD_PRELOAD_DISABLE;
  if (HAL_TIM_Base_Init(&htim17) != HAL_OK)
  {
    Error_Handler();
  }
  if (HAL_TIM_OC_Init(&htim17) != HAL_OK)
  {
    Error_Handler();
  }
  sConfigOC.OCMode = TIM_OCMODE_TIMING;
  sConfigOC.Pulse = 0;
  sConfigOC.OCPolarity = TIM_OCPOLARITY_HIGH;
  sConfigOC.OCNPolarity = TIM_OCNPOLARITY_HIGH;
  sConfigOC.OCFastMode = TIM_OCFAST_DISABLE;
  sConfigOC.OCIdleState = TIM_OCIDLESTATE_RESET;
  sConfigOC.OCNIdleState = TIM_OCNIDLESTATE_RESET;
  if (HAL_TIM_OC_ConfigChannel(&htim17, &sConfigOC, TIM_CHANNEL_1) != HAL_OK)
  {
    Error_Handler();
  }
  sBreakDeadTimeConfig.OffStateRunMode = TIM_OSSR_DISABLE;
  sBreakDeadTimeConfig.OffStateIDLEMode = TIM_OSSI_DISABLE;
  sBreakDeadTimeConfig.LockLevel = TIM_LOCKLEVEL_OFF;
  sBreakDeadTimeConfig.DeadTime = 0;
  sBreakDeadTimeConfig.BreakState = TIM_BREAK_DISABLE;
  sBreakDeadTimeConfig.BreakPolarity = TIM_BREAKPOLARITY_HIGH;
  sBreakDeadTimeConfig.BreakFilter = 0;
  sBreakDeadTimeConfig.AutomaticOutput = TIM_AUTOMATICOUTPUT_DISABLE;
  if (HAL_TIMEx_ConfigBreakDeadTime(&htim17, &sBreakDeadTimeConfig) != HAL_OK)
  {
    Error_Handler();
  }

}

static void MX_UART4_Init(void)
{

  huart4.Instance = UART4;
  huart4.Init.BaudRate = 115200;
  huart4.Init.WordLength = UART_WORDLENGTH_8B;
  huart4.Init.StopBits = UART_STOPBITS_1;
  huart4.Init.Parity = UART_PARITY_NONE;
  huart4.Init.Mode = UART_MODE_TX_RX;
  huart4.Init.HwFlowCtl = UART_HWCONTROL_NONE;
  huart4.Init.OverSampling = UART_OVERSAMPLING_16;
  huart4.Init.OneBitSampling = UART_ONE_BIT_SAMPLE_DISABLE;
  huart4.Init.ClockPrescaler = UART_PRESCALER_DIV1;
  huart4.AdvancedInit.AdvFeatureInit = UART_ADVFEATURE_NO_INIT;
  if (HAL_UART_Init(&huart4) != HAL_OK)
  {
    Error_Handler();
  }
  if (HAL_UARTEx_SetTxFifoThreshold(&huart4, UART_TXFIFO_THRESHOLD_1_8) != HAL_OK)
  {
    Error_Handler();
  }
  if (HAL_UARTEx_SetRxFifoThreshold(&huart4, UART_RXFIFO_THRESHOLD_1_8) != HAL_OK)
  {
    Error_Handler();
  }
  if (HAL_UARTEx_DisableFifoMode(&huart4) != HAL_OK)
  {
    Error_Handler();
  }

}

static void MX_UART7_Init(void)
{

  huart7.Instance = UART7;
  huart7.Init.BaudRate = 115200;
  huart7.Init.WordLength = UART_WORDLENGTH_8B;
  huart7.Init.StopBits = UART_STOPBITS_1;
  huart7.Init.Parity = UART_PARITY_NONE;
  huart7.Init.Mode = UART_MODE_TX_RX;
  huart7.Init.HwFlowCtl = UART_HWCONTROL_NONE;
  huart7.Init.OverSampling = UART_OVERSAMPLING_16;
  huart7.Init.OneBitSampling = UART_ONE_BIT_SAMPLE_DISABLE;
  huart7.Init.ClockPrescaler = UART_PRESCALER_DIV1;
  huart7.AdvancedInit.AdvFeatureInit = UART_ADVFEATURE_NO_INIT;
  if (HAL_UART_Init(&huart7) != HAL_OK)
  {
    Error_Handler();
  }
  if (HAL_UARTEx_SetTxFifoThreshold(&huart7, UART_TXFIFO_THRESHOLD_1_8) != HAL_OK)
  {
    Error_Handler();
  }
  if (HAL_UARTEx_SetRxFifoThreshold(&huart7, UART_RXFIFO_THRESHOLD_1_8) != HAL_OK)
  {
    Error_Handler();
  }
  if (HAL_UARTEx_DisableFifoMode(&huart7) != HAL_OK)
  {
    Error_Handler();
  }

}

static void MX_USART1_UART_Init(void)
{

  huart1.Instance = USART1;
  huart1.Init.BaudRate = 115200;
  huart1.Init.WordLength = UART_WORDLENGTH_8B;
  huart1.Init.StopBits = UART_STOPBITS_1;
  huart1.Init.Parity = UART_PARITY_NONE;
  huart1.Init.Mode = UART_MODE_TX_RX;
  huart1.Init.HwFlowCtl = UART_HWCONTROL_NONE;
  huart1.Init.OverSampling = UART_OVERSAMPLING_16;
  huart1.Init.OneBitSampling = UART_ONE_BIT_SAMPLE_DISABLE;
  huart1.Init.ClockPrescaler = UART_PRESCALER_DIV1;
  huart1.AdvancedInit.AdvFeatureInit = UART_ADVFEATURE_NO_INIT;
  if (HAL_UART_Init(&huart1) != HAL_OK)
  {
    Error_Handler();
  }
  if (HAL_UARTEx_SetTxFifoThreshold(&huart1, UART_TXFIFO_THRESHOLD_1_8) != HAL_OK)
  {
    Error_Handler();
  }
  if (HAL_UARTEx_SetRxFifoThreshold(&huart1, UART_RXFIFO_THRESHOLD_1_8) != HAL_OK)
  {
    Error_Handler();
  }
  if (HAL_UARTEx_DisableFifoMode(&huart1) != HAL_OK)
  {
    Error_Handler();
  }

}

static void MX_USART2_UART_Init(void)
{

  huart2.Instance = USART2;
  huart2.Init.BaudRate = 115200;
  huart2.Init.WordLength = UART_WORDLENGTH_8B;
  huart2.Init.StopBits = UART_STOPBITS_1;
  huart2.Init.Parity = UART_PARITY_NONE;
  huart2.Init.Mode = UART_MODE_TX_RX;
  huart2.Init.HwFlowCtl = UART_HWCONTROL_NONE;
  huart2.Init.OverSampling = UART_OVERSAMPLING_16;
  huart2.Init.OneBitSampling = UART_ONE_BIT_SAMPLE_DISABLE;
  huart2.Init.ClockPrescaler = UART_PRESCALER_DIV1;
  huart2.AdvancedInit.AdvFeatureInit = UART_ADVFEATURE_NO_INIT;
  if (HAL_UART_Init(&huart2) != HAL_OK)
  {
    Error_Handler();
  }
  if (HAL_UARTEx_SetTxFifoThreshold(&huart2, UART_TXFIFO_THRESHOLD_1_8) != HAL_OK)
  {
    Error_Handler();
  }
  if (HAL_UARTEx_SetRxFifoThreshold(&huart2, UART_RXFIFO_THRESHOLD_1_8) != HAL_OK)
  {
    Error_Handler();
  }
  if (HAL_UARTEx_DisableFifoMode(&huart2) != HAL_OK)
  {
    Error_Handler();
  }

}

static void MX_USART3_UART_Init(void)
{

  huart3.Instance = USART3;
  huart3.Init.BaudRate = 115200;
  huart3.Init.WordLength = UART_WORDLENGTH_8B;
  huart3.Init.StopBits = UART_STOPBITS_1;
  huart3.Init.Parity = UART_PARITY_NONE;
  huart3.Init.Mode = UART_MODE_TX_RX;
  huart3.Init.HwFlowCtl = UART_HWCONTROL_NONE;
  huart3.Init.OverSampling = UART_OVERSAMPLING_16;
  huart3.Init.OneBitSampling = UART_ONE_BIT_SAMPLE_DISABLE;
  huart3.Init.ClockPrescaler = UART_PRESCALER_DIV1;
  huart3.AdvancedInit.AdvFeatureInit = UART_ADVFEATURE_NO_INIT;
  if (HAL_UART_Init(&huart3) != HAL_OK)
  {
    Error_Handler();
  }
  if (HAL_UARTEx_SetTxFifoThreshold(&huart3, UART_TXFIFO_THRESHOLD_1_8) != HAL_OK)
  {
    Error_Handler();
  }
  if (HAL_UARTEx_SetRxFifoThreshold(&huart3, UART_RXFIFO_THRESHOLD_1_8) != HAL_OK)
  {
    Error_Handler();
  }
  if (HAL_UARTEx_DisableFifoMode(&huart3) != HAL_OK)
  {
    Error_Handler();
  }

}

static void MX_USART6_UART_Init(void)
{

  huart6.Instance = USART6;
  huart6.Init.BaudRate = 115200;
  huart6.Init.WordLength = UART_WORDLENGTH_8B;
  huart6.Init.StopBits = UART_STOPBITS_1;
  huart6.Init.Parity = UART_PARITY_NONE;
  huart6.Init.Mode = UART_MODE_TX_RX;
  huart6.Init.HwFlowCtl = UART_HWCONTROL_NONE;
  huart6.Init.OverSampling = UART_OVERSAMPLING_16;
  huart6.Init.OneBitSampling = UART_ONE_BIT_SAMPLE_DISABLE;
  huart6.Init.ClockPrescaler = UART_PRESCALER_DIV1;
  huart6.AdvancedInit.AdvFeatureInit = UART_ADVFEATURE_NO_INIT;
  if (HAL_UART_Init(&huart6) != HAL_OK)
  {
    Error_Handler();
  }
  if (HAL_UARTEx_SetTxFifoThreshold(&huart6, UART_TXFIFO_THRESHOLD_1_8) != HAL_OK)
  {
    Error_Handler();
  }
  if (HAL_UARTEx_SetRxFifoThreshold(&huart6, UART_RXFIFO_THRESHOLD_1_8) != HAL_OK)
  {
    Error_Handler();
  }
  if (HAL_UARTEx_DisableFifoMode(&huart6) != HAL_OK)
  {
    Error_Handler();
  }

}

/* FMC initialization function */
static void MX_FMC_Init(void)
{

  FMC_SDRAM_TimingTypeDef SdramTiming = {0};

  /** Perform the SDRAM1 memory initialization sequence
  */
  hsdram1.Instance = FMC_SDRAM_DEVICE;
  /* hsdram1.Init */
  hsdram1.Init.SDBank = FMC_SDRAM_BANK1;
  hsdram1.Init.ColumnBitsNumber = FMC_SDRAM_COLUMN_BITS_NUM_9;
  hsdram1.Init.RowBitsNumber = FMC_SDRAM_ROW_BITS_NUM_13;
  hsdram1.Init.MemoryDataWidth = FMC_SDRAM_MEM_BUS_WIDTH_16;
  hsdram1.Init.InternalBankNumber = FMC_SDRAM_INTERN_BANKS_NUM_4;
  hsdram1.Init.CASLatency = FMC_SDRAM_CAS_LATENCY_3;
  hsdram1.Init.WriteProtection = FMC_SDRAM_WRITE_PROTECTION_DISABLE;
  hsdram1.Init.SDClockPeriod = FMC_SDRAM_CLOCK_PERIOD_2;
  hsdram1.Init.ReadBurst = FMC_SDRAM_RBURST_ENABLE;
  hsdram1.Init.ReadPipeDelay = FMC_SDRAM_RPIPE_DELAY_1;
  /* SdramTiming */
  SdramTiming.LoadToActiveDelay = 2;
  SdramTiming.ExitSelfRefreshDelay = 7;
  SdramTiming.SelfRefreshTime = 4;
  SdramTiming.RowCycleDelay = 7;
  SdramTiming.WriteRecoveryTime = 3;
  SdramTiming.RPDelay = 2;
  SdramTiming.RCDDelay = 2;

  if (HAL_SDRAM_Init(&hsdram1, &SdramTiming) != HAL_OK)
  {
    Error_Handler( );
  }

  /* USER CODE BEGIN FMC_Init 2 */
  SDRAM_Init(&hsdram1);
  /* USER CODE END FMC_Init 2 */
}

static void MX_GPIO_Init(void)
{
  GPIO_InitTypeDef GPIO_InitStruct = {0};

  /* GPIO Ports Clock Enable */
  __HAL_RCC_GPIOI_CLK_ENABLE();
  __HAL_RCC_GPIOK_CLK_ENABLE();
  __HAL_RCC_GPIOG_CLK_ENABLE();
  __HAL_RCC_GPIOD_CLK_ENABLE();
  __HAL_RCC_GPIOE_CLK_ENABLE();
  __HAL_RCC_GPIOB_CLK_ENABLE();
  __HAL_RCC_GPIOJ_CLK_ENABLE();
  __HAL_RCC_GPIOH_CLK_ENABLE();
  __HAL_RCC_GPIOA_CLK_ENABLE();
  __HAL_RCC_GPIOC_CLK_ENABLE();
  __HAL_RCC_GPIOF_CLK_ENABLE();

  /*Configure GPIO pin Output Level */
  HAL_GPIO_WritePin(LED_GPIO_Port, LED_Pin, GPIO_PIN_SET);

  /*Configure GPIO pin Output Level */
  HAL_GPIO_WritePin(TOUCH_RST_GPIO_Port, TOUCH_RST_Pin, GPIO_PIN_SET);

  /*Configure GPIO pin Output Level */
  HAL_GPIO_WritePin(TOUCH_INT_GPIO_Port, TOUCH_INT_Pin, GPIO_PIN_RESET);

  /*Configure GPIO pin Output Level */
  HAL_GPIO_WritePin(GPIOG, TOUCH_SDA_Pin|TOUCH_SCL_Pin, GPIO_PIN_SET);

  /*Configure GPIO pin Output Level */
  HAL_GPIO_WritePin(LCD_BLK_GPIO_Port, LCD_BLK_Pin, GPIO_PIN_SET);

  /*Configure GPIO pin : K0_Pin */
  GPIO_InitStruct.Pin = K0_Pin;
  GPIO_InitStruct.Mode = GPIO_MODE_INPUT;
  GPIO_InitStruct.Pull = GPIO_PULLUP;
  HAL_GPIO_Init(K0_GPIO_Port, &GPIO_InitStruct);

  /*Configure GPIO pin : LED_Pin */
  GPIO_InitStruct.Pin = LED_Pin;
  GPIO_InitStruct.Mode = GPIO_MODE_OUTPUT_PP;
  GPIO_InitStruct.Pull = GPIO_NOPULL;
  GPIO_InitStruct.Speed = GPIO_SPEED_FREQ_LOW;
  HAL_GPIO_Init(LED_GPIO_Port, &GPIO_InitStruct);

  /*Configure GPIO pins : TOUCH_RST_Pin TOUCH_INT_Pin */
  GPIO_InitStruct.Pin = TOUCH_RST_Pin|TOUCH_INT_Pin;
  GPIO_InitStruct.Mode = GPIO_MODE_OUTPUT_PP;
  GPIO_InitStruct.Pull = GPIO_PULLUP;
  GPIO_InitStruct.Speed = GPIO_SPEED_FREQ_LOW;
  HAL_GPIO_Init(GPIOI, &GPIO_InitStruct);

  /*Configure GPIO pins : TOUCH_SDA_Pin TOUCH_SCL_Pin */
  GPIO_InitStruct.Pin = TOUCH_SDA_Pin|TOUCH_SCL_Pin;
  GPIO_InitStruct.Mode = GPIO_MODE_OUTPUT_OD;
  GPIO_InitStruct.Pull = GPIO_NOPULL;
  GPIO_InitStruct.Speed = GPIO_SPEED_FREQ_LOW;
  HAL_GPIO_Init(GPIOG, &GPIO_InitStruct);

  /*Configure GPIO pin : PG6 */
  GPIO_InitStruct.Pin = GPIO_PIN_6;
  GPIO_InitStruct.Mode = GPIO_MODE_AF_PP;
  GPIO_InitStruct.Pull = GPIO_NOPULL;
  GPIO_InitStruct.Speed = GPIO_SPEED_FREQ_VERY_HIGH;
  GPIO_InitStruct.Alternate = GPIO_AF10_QUADSPI;
  HAL_GPIO_Init(GPIOG, &GPIO_InitStruct);

  /*Configure GPIO pin : PF7 */
  GPIO_InitStruct.Pin = GPIO_PIN_7;
  GPIO_InitStruct.Mode = GPIO_MODE_AF_PP;
  GPIO_InitStruct.Pull = GPIO_NOPULL;
  GPIO_InitStruct.Speed = GPIO_SPEED_FREQ_VERY_HIGH;
  GPIO_InitStruct.Alternate = GPIO_AF9_QUADSPI;
  HAL_GPIO_Init(GPIOF, &GPIO_InitStruct);

  /*Configure GPIO pins : PF8 PF9 */
  GPIO_InitStruct.Pin = GPIO_PIN_8|GPIO_PIN_9;
  GPIO_InitStruct.Mode = GPIO_MODE_AF_PP;
  GPIO_InitStruct.Pull = GPIO_NOPULL;
  GPIO_InitStruct.Speed = GPIO_SPEED_FREQ_VERY_HIGH;
  GPIO_InitStruct.Alternate = GPIO_AF10_QUADSPI;
  HAL_GPIO_Init(GPIOF, &GPIO_InitStruct);

  /*Configure GPIO pins : PH10 PH9 PH12 */
  GPIO_InitStruct.Pin = GPIO_PIN_10|GPIO_PIN_9|GPIO_PIN_12;
  GPIO_InitStruct.Mode = GPIO_MODE_AF_PP;
  GPIO_InitStruct.Pull = GPIO_NOPULL;
  GPIO_InitStruct.Speed = GPIO_SPEED_FREQ_VERY_HIGH;
  GPIO_InitStruct.Alternate = GPIO_AF13_DCMI;
  HAL_GPIO_Init(GPIOH, &GPIO_InitStruct);

  /*Configure GPIO pin : LCD_BLK_Pin */
  GPIO_InitStruct.Pin = LCD_BLK_Pin;
  GPIO_InitStruct.Mode = GPIO_MODE_OUTPUT_PP;
  GPIO_InitStruct.Pull = GPIO_NOPULL;
  GPIO_InitStruct.Speed = GPIO_SPEED_FREQ_LOW;
  HAL_GPIO_Init(LCD_BLK_GPIO_Port, &GPIO_InitStruct);

}

void vTouchgfxTask(void *argument)
{
  /* USER CODE BEGIN 5 */
  /* Infinite loop */
    MX_TouchGFX_Process();	// ����TouchGFX����
	for(;;)
	{
		osDelay(10);
	}
  /* USER CODE END 5 */
}

 /* MPU Configuration */

void MPU_Config(void)
{
  MPU_Region_InitTypeDef MPU_InitStruct = {0};

  /* Disables the MPU */
  HAL_MPU_Disable();

  /** Initializes and configures the Region and the memory to be protected
  */
  MPU_InitStruct.Enable = MPU_REGION_ENABLE;
  MPU_InitStruct.Number = MPU_REGION_NUMBER0;
  MPU_InitStruct.BaseAddress = 0xC0000000;
  MPU_InitStruct.Size = MPU_REGION_SIZE_32MB;
  MPU_InitStruct.SubRegionDisable = 0x0;
  MPU_InitStruct.TypeExtField = MPU_TEX_LEVEL0;
  MPU_InitStruct.AccessPermission = MPU_REGION_FULL_ACCESS;
  MPU_InitStruct.DisableExec = MPU_INSTRUCTION_ACCESS_ENABLE;
  MPU_InitStruct.IsShareable = MPU_ACCESS_NOT_SHAREABLE;
  MPU_InitStruct.IsCacheable = MPU_ACCESS_CACHEABLE;
  MPU_InitStruct.IsBufferable = MPU_ACCESS_NOT_BUFFERABLE;

  HAL_MPU_ConfigRegion(&MPU_InitStruct);
  /* Enables the MPU */
  HAL_MPU_Enable(MPU_PRIVILEGED_DEFAULT);

}

void HAL_TIM_PeriodElapsedCallback(TIM_HandleTypeDef *htim)
{
  if (htim->Instance == TIM6)
  {
    HAL_IncTick();
  }
  /* USER CODE BEGIN Callback 1 */
  if (htim->Instance == TIM17) {
    KeyHandle(&K0,K0_GPIO_Port,K0_Pin);
  }
  /* USER CODE END Callback 1 */
}

void Error_Handler(void)
{
  __disable_irq();
  while (1)
  {
  }
}
